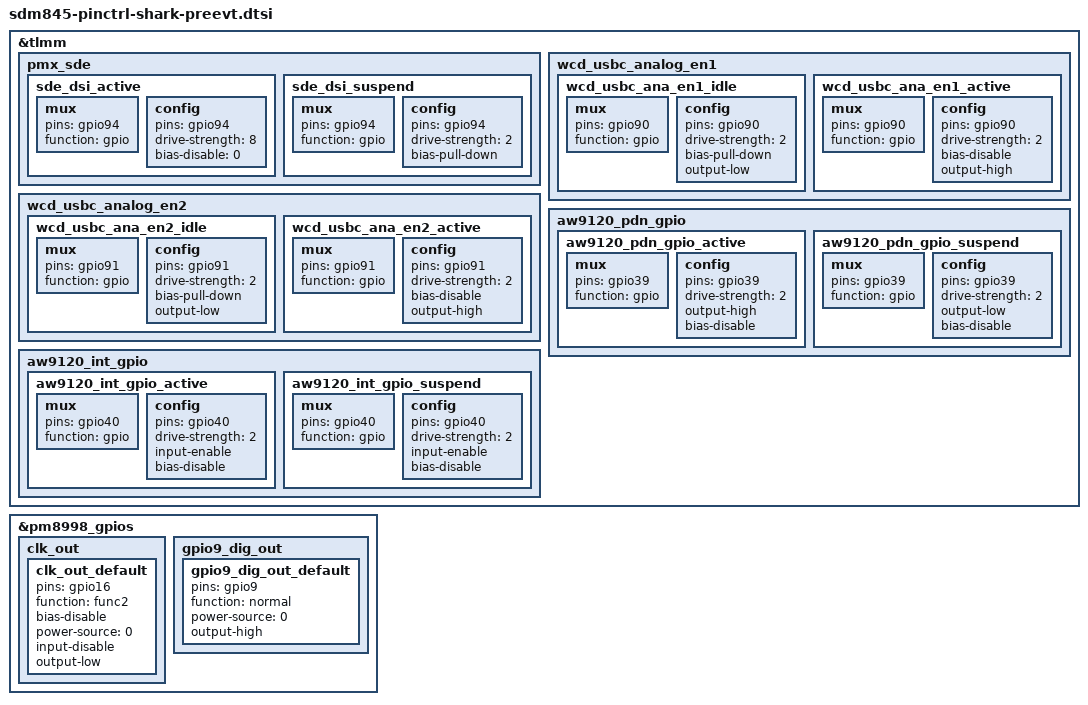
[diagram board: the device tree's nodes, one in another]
/*
 * Copyright (c) 2015-2016, The Linux Foundation. All rights reserved.
 *
 * This program is free software; you can redistribute it and/or modify
 * it under the terms of the GNU General Public License version 2 and
 * only version 2 as published by the Free Software Foundation.
 *
 * This program is distributed in the hope that it will be useful,
 * but WITHOUT ANY WARRANTY; without even the implied warranty of
 * MERCHANTABILITY or FITNESS FOR A PARTICULAR PURPOSE.  See the
 * GNU General Public License for more details.
 */
&tlmm {
	/******************** LCD **************************/
	pmx_sde {
		sde_dsi_active {
			mux {
				pins = "gpio94";
				function = "gpio";
			};

			config {
				pins = "gpio94";
				drive-strength = <8>;   /* 8 mA */
				bias-disable = <0>;   /* no pull */
			};
		};
		sde_dsi_suspend {
			mux {
				pins = "gpio94";
				function = "gpio";
			};

			config {
				pins = "gpio94";
				drive-strength = <2>;   /* 2 mA */
				bias-pull-down;         /* PULL DOWN */
			};
		};
	};

	/* USB C analog configuration */
	wcd_usbc_analog_en1 {
		wcd_usbc_ana_en1_idle {
			mux {
				pins = "gpio90";
				function = "gpio";
			};
			config {
				pins = "gpio90";
				drive-strength = <2>;
				bias-pull-down;
				output-low;
			};
		};

		wcd_usbc_ana_en1_active {
			mux {
				pins = "gpio90";
				function = "gpio";
			};
			config {
				pins = "gpio90";
				drive-strength = <2>;
				bias-disable;
				output-high;
			};
		};
	};

	wcd_usbc_analog_en2 {
		wcd_usbc_ana_en2_idle {
			mux {
				pins = "gpio91";
				function = "gpio";
			};
			config {
				pins = "gpio91";
				drive-strength = <2>;
				bias-pull-down;
				output-low;
			};
		};

		wcd_usbc_ana_en2_active {
			mux {
				pins = "gpio91";
				function = "gpio";
			};
			config {
				pins = "gpio91";
				drive-strength = <2>;
				bias-disable;
				output-high;
			};
		};
	};


	/*********** aw9120 led pin start*****/
	aw9120_pdn_gpio {
		aw9120_pdn_gpio_active: aw9120_pdn_gpio_active{
			mux{
				pins = "gpio39";
				function = "gpio";
			};
			config {
				pins = "gpio39";
				drive-strength = <2>;
				output-high;
				bias-disable;
			};
		};
		aw9120_pdn_gpio_suspend: aw9120_pdn_gpio_suspend{
			mux{
				pins = "gpio39";
				function = "gpio";
			};
			config {
				pins = "gpio39";
				drive-strength = <2>;
				output-low;
				bias-disable;
			};
		};
	};
	aw9120_int_gpio {
		aw9120_int_gpio_active: aw9120_int_gpio_active{
			mux{
				pins = "gpio40";
				function = "gpio";
			};
			config {
				pins = "gpio40";
				drive-strength = <2>;
				input-enable;
				bias-disable;
			};
		};
		aw9120_int_gpio_suspend: aw9120_int_gpio_suspend{
			mux{
				pins = "gpio40";
				function = "gpio";
			};
			config {
				pins = "gpio40";
				drive-strength = <2>;
				input-enable;
				bias-disable;
			};
		};
	};
	/*********** aw9120 led pin end*****/
};

&pm8998_gpios {
	clk_out {
		clk_out_default: clk_out_default {
		pins = "gpio16"; /* GPIO 16 */
		function = "func2"; /* Special Function 1 */
		bias-disable; /* No Pull */
		power-source = <0>; /* VIN0 */
		input-disable;
		output-low; /* digital output, no invert */
		};
	};

	gpio9_dig_out {
		gpio9_dig_out_default: gpio9_dig_out_default {
			pins = "gpio9"; /* GPIO 9 */
			function = "normal"; /* normal output */
			power-source = <0>; /* VIN0 */
			output-high; /* digital output, no invert */
		};
	};

};
